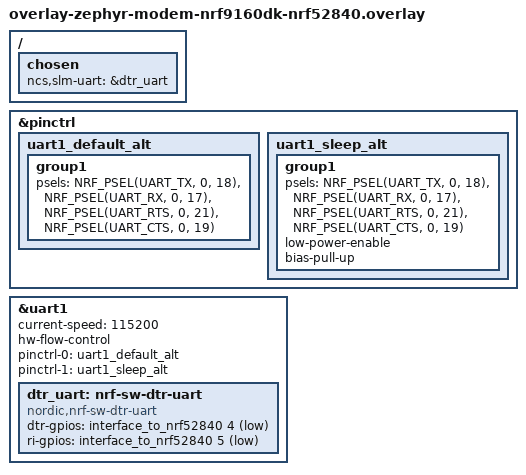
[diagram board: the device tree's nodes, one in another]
/*
 * Copyright (c) 2024 Nordic Semiconductor ASA
 *
 * SPDX-License-Identifier: LicenseRef-Nordic-5-Clause
 */

&pinctrl {
	uart1_default_alt: uart1_default_alt {
		group1 {
			psels = <NRF_PSEL(UART_TX, 0, 18)>,
				<NRF_PSEL(UART_RX, 0, 17)>,
				<NRF_PSEL(UART_RTS, 0, 21)>,
				<NRF_PSEL(UART_CTS, 0, 19)>;
		};
	};

	uart1_sleep_alt: uart1_sleep_alt {
		group1 {
			psels = <NRF_PSEL(UART_TX, 0, 18)>,
				<NRF_PSEL(UART_RX, 0, 17)>,
				<NRF_PSEL(UART_RTS, 0, 21)>,
				<NRF_PSEL(UART_CTS, 0, 19)>;
			low-power-enable;
			bias-pull-up;
		};
	};

};

/ {
	chosen {
		ncs,slm-uart = &dtr_uart;
	};
};

&uart1 {
        current-speed = <115200>;
        hw-flow-control;
	status = "okay";
	pinctrl-0 = <&uart1_default_alt>;
	pinctrl-1 = <&uart1_sleep_alt>;
	pinctrl-names = "default", "sleep";

	dtr_uart: nrf-sw-dtr-uart {
		compatible = "nordic,nrf-sw-dtr-uart";
		dtr-gpios = <&interface_to_nrf52840 4 (GPIO_PULL_UP | GPIO_ACTIVE_LOW)>;
		ri-gpios = <&interface_to_nrf52840 5 (GPIO_ACTIVE_LOW)>;
		status = "okay";
	};
};
